# ADuCM410 register map
Vendor: Analog Devices; Series: ADuCM410; File version: 1p0
CPU: CM33 r0p1, little endian, MPU, FPU, 3 interrupt priority bits
Registers are 32-bit, read-write, reset 0x0 unless marked. A register's access mark holds for its fields unless they carry their own. Offsets are from the block's base; [hi:lo] are bit positions; {n}, {i} and the like mark numbered series; 'fields as' and 'values as' point back to an identical list.

## PGA
Base 0x40069000
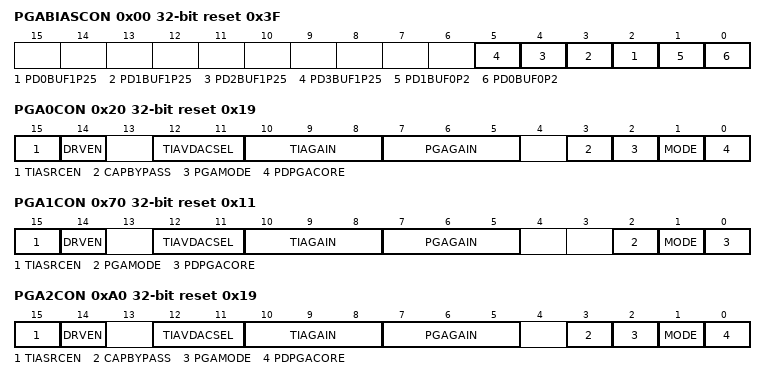
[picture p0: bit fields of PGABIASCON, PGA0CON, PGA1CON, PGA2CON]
0x00 PGABIASCON reset 0x3F — PGA Bias Circuit Control Signal
  [n+2] PD{n}BUF1P25 (n=0..3) — BUF1P25 Power Down
    0=ENABLE (BUF1p25 Enable); 1=OFF (BUF1p25 Power Down)
  [1] PD1BUF0P2 — Buf_200mv Power Down
    0=ENABLE (Buf_200mV Enable); 1=OFF (Buf_200mv Power Down)
  [0] PD0BUF0P2 — Buf_200mv Power Down
    0=ENABLE (Buf_200mV Enable); 1=OFF (Buf_200mv Power Down)
0x20 PGA0CON reset 0x19 — PGA0 Control Register
  [15] TIASRCEN — Select Between Source Mode and Sink Mode
    0=SINKMD (Sink Mode); 1=SOURCEMD (Source Mode)
  [14] DRVEN — Sink Current Ability Improve
    0=DRVDISABLE (Disable Isink Ability Improvement, Normal Drive); 1=DRVENABLE (Enable Isink Ability Improvement)
  [12:11] TIAVDACSEL — TIA Vbias Selection of VDAC Channel
    {v}=VDAC{v+8}SEL (Select VDAC{v+8} as TIA Vbias) (v=0..3)
  [10:8] TIAGAIN — TIA Gain Configuration
    0=RES250 (TIARES=250ohm); 1=RES750 (TIARES=750ohm); 2=RES2K (TIARES=2kohm); 3=RES5K (TIARES=5kohm); 4=RES10K (TIARES=10kohm); 5=RES20k (TIARES=20kohm); 6=RES100K (TIARES=100kohm)
  [7:5] PGAGAIN — PGA Gain Configuration
    0=GAIN1; 1=GAIN2; 2=GAIN4; 3=GAIN6; 4=GAIN8; 5=GAIN10
  [3] CAPBYPASS — Bypass the External Cap
    0=BYPDISABLE (Select the External CAP); 1=BYPEN (Bypass the External Cap)
  [2] PGAMODE — PGA DC Mode or AC Couple Mode Selection
    0=DCCOUPLE (PGA DC Mode Enable); 1=ACCOUPLE (PGA AC Coupling Mode Enable)
  [1] MODE — PGA or TIA Mode Selection
    0=PGAMODE (PGA Mode Enable); 1=TIAMODE (TIA Mode Enable)
  [0] PDPGACORE — PGA Core Power Down
0x24 PGA0CHPCON reset 0x1 — PGA0 Chop Function Ctrl
  [0] CHOPOFF — Disable Chop Function
    0=CHOPEN (Enable Chop Function); 1=CHOPDIS (Disable Chop Function)
0x28 PGA3CHPCON reset 0x1 — PGA3 Chop Function Ctrl
  fields as PGA0CHPCON
0x70 PGA1CON reset 0x11 — PGA1 Control Register
  [15] TIASRCEN — Select Between Source Mode and Sink Mode
    0=SINKMD (Sink Mode); 1=SOURCEMD (Source Mode)
  [14] DRVEN — Sink Current Ability Improve
    values as PGA0CON.DRVEN
  [12:11] TIAVDACSEL — TIA Vbias Selection of VDAC Channel
    {v}=VDAC{v+8}SEL (Select VDAC{v+8} as TIA Vbias) (v=0..3)
  [10:8] TIAGAIN — TIA Gain Configuration
    values as PGA0CON.TIAGAIN
  [7:5] PGAGAIN — PGA Gain Configuration
    0=GAIN1; 1=GAIN2; 2=GAIN4; 3=GAIN6; 4=GAIN8; 5=GAIN10
  [2] PGAMODE — PGA DC Mode or AC Couple Mode Selection
    values as PGA0CON.PGAMODE
  [1] MODE — PGA or TIA Mode Selection
    0=PGAMODE (PGA Mode Enable); 1=TIAMODE (TIA Mode Enable)
  [0] PDPGACORE — PGA Core Power Down
0x74 PGA1CHPCON reset 0x1 — PGA1 Chop Function Ctrl
  fields as PGA0CHPCON
0xA0 PGA2CON reset 0x19 — PGA2 Control Register
  fields as PGA0CON
0xA4 PGA2CHPCON reset 0x1 — PGA2 Chop Function Ctrl
  fields as PGA0CHPCON
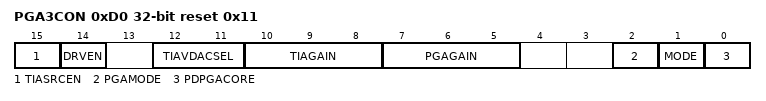
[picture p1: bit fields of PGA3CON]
0xD0 PGA3CON reset 0x11 — PGA3 Control Register
  fields as PGA1CON

## PLL
Base 0x40069200
0x00 PLLPDCTRL reset 0x3F
  [6] TOTPDB range 0x00000000..0x00000001 — PDB of PLL All

## TMPSNS
Base 0x40069600
0x00 TMPSNSCON reset 0x2
  [1] ENTMPSNS range 0x00000000..0x00000001 — Enable Temp Sensor
0x04 TMPSNSCHPCON
  [0] CHOFFTMPSNS range 0x00000000..0x00000001 — Chopping Disable = 1 Enable = 0
0x08 VCMREFCON
  [1] PGAREFSEL — 0.2V or 0.5V Selection for PGA
    0=SEL0P2V (Select 0.2V Reference); 1=SEL0P5V (Select 0.5V Reference)
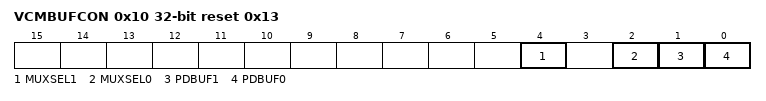
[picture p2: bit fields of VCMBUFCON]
0x10 VCMBUFCON reset 0x13
  [4] MUXSEL1 — Selection 0=2.5V 1=1.25V
    0=BUF1_2P5 (Buffer1 Input 2.5V); 1=BUF1_1P25 (Buffer1 Input 1.25V)
  [2] MUXSEL0 — Selection 0=2.5V 1=1.25V
    0=BUF0_2P5 (Input Buffer0 2.5V); 1=BUF0_1P25 (Input Buffer0 1.25V)
  [1] PDBUF1 range 0x00000000..0x00000001 — Power Down Unit Gain Buffer1
  [0] PDBUF0 range 0x00000000..0x00000001 — Power Down Unit Gain Buffer0

## VDAC
Base 0x40069800
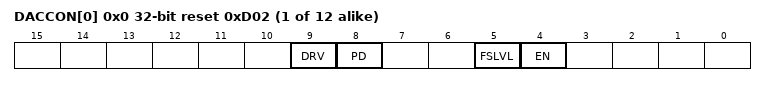
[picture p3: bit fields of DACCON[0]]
{0x0+4i} DACCON[{i}] (i=0..11) reset 0xD02 — DAC Control Register
  [9] DRV — Drive Ability Boost Enable, Can Drive 10mA Load.
    0=NORMAL (Normal Work Mode); 1=DRIVEBOOST (Drive Ability Boost Mode)
  [8] PD — DAC Top Power Down
    0=DACON (DAC Top Enable); 1=DACOFF (DAC TOP Power Down)
  [5] FSLVL — Select Output Full Scale
    0=OUT2P5 (Full Scale is 2.5V); 1=OUT3V3 (Full Scale is 3.3V)
  [4] EN — DAC Input Data Clear, Won't Be Controlled by Sync Mode.
    0=CLEAR (DAC DATA Clear); 1=CLEAROFF (DAC DATA Normal Input)
{0x30+4i} DACDAT[{i}] (i=0..11) — DAC Data Register
  [27:12] DATAIN range 0x00000000..0x0000FFFF — DAC Input Data
